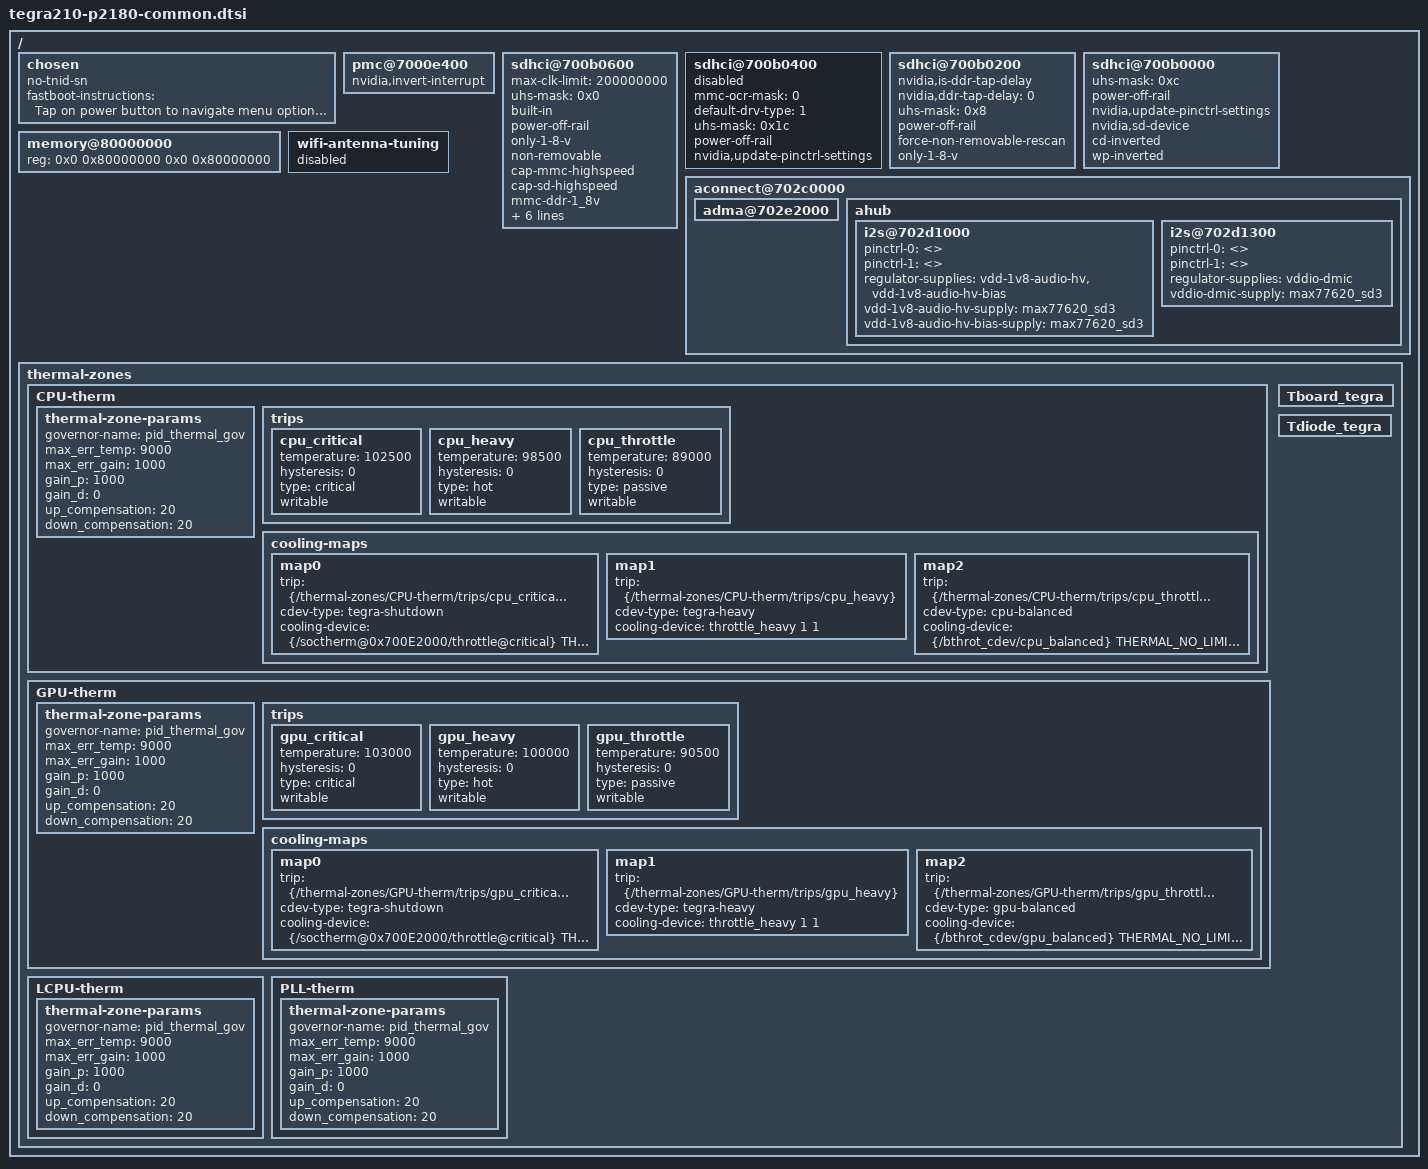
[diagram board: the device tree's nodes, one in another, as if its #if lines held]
/*
 * arch/arm64/boot/dts/tegra210-platforms/tegra210-p2180-common.dtsi
 *
 * Copyright (c) 2015-2016, NVIDIA CORPORATION.  All rights reserved.
 *
 * This program is free software; you can redistribute it and/or modify
 * it under the terms of the GNU General Public License as published by
 * the Free Software Foundation; version 2 of the License.
 *
 * This program is distributed in the hope that it will be useful, but WITHOUT
 * ANY WARRANTY; without even the implied warranty of MERCHANTABILITY or
 * FITNESS FOR A PARTICULAR PURPOSE.  See the GNU General Public License for
 * more details.
 *
 * You should have received a copy of the GNU General Public License along
 * with this program; if not, write to the Free Software Foundation, Inc.,
 * 51 Franklin Street, Fifth Floor, Boston, MA  02110-1301, USA.
 *
 */

#include <t210-common-platforms/tegra210-thermal-nct72-p2530.dtsi>
#include <tegra210-soc/tegra210-thermal-Tboard-Tdiode.dtsi>

/ {
	#address-cells = <2>;
	#size-cells = <2>;

	chosen {
		no-tnid-sn;
		fastboot-instructions = "Tap on power button to navigate menu options.\nHold down power button for 2 sec and release for selecting an option\n";
	};

	pmc@7000e400 {
		nvidia,invert-interrupt;
	};

	sdhci@700b0600 {
		max-clk-limit = <200000000>;
		uhs-mask = <0x0>;
		built-in;
		power-off-rail;
		only-1-8-v;
		non-removable;
		cap-mmc-highspeed;
		cap-sd-highspeed;
		mmc-ddr-1_8v;
		mmc-hs200-1_8v;
		mmc-hs400-1_8v;
		mmc-hs400-enhanced-strobe;
		no-sdio;
		no-sd;
		pll_source = "pll_p", "pll_c4_out2";
		status = "okay";
	};

	sdhci@700b0400 {
		mmc-ocr-mask = <0>;
		default-drv-type = <1>;
		uhs-mask = <0x1c>;
		power-off-rail;
		nvidia,update-pinctrl-settings;
		status = "disabled";
	};

	sdhci@700b0200 {
		nvidia,is-ddr-tap-delay;
		nvidia,ddr-tap-delay = <0>;
		uhs-mask = <0x8>;
		power-off-rail;
		force-non-removable-rescan;
		only-1-8-v;
		status = "okay";
	};

	sdhci@700b0000 {
		uhs-mask = <0xc>;
		power-off-rail;
		nvidia,update-pinctrl-settings;
		nvidia,sd-device;
		cd-inverted;
		wp-inverted;
		status = "okay";
	};

	memory@80000000 {
		device_type = "memory";
		reg = < 0x0 0x80000000 0x0 0x80000000 >;
	};

#if TEGRA_AUDIO_BUS_DT_VERSION >= DT_VERSION_2
	aconnect@702c0000 {
#endif
	adma@702e2000  {
		status = "okay";
	};


	ahub {
		i2s@702d1000 {
			pinctrl-names = "dap_active", "dap_inactive";
			pinctrl-0 = <>;
			pinctrl-1 = <>;
			regulator-supplies = "vdd-1v8-audio-hv", "vdd-1v8-audio-hv-bias";
			vdd-1v8-audio-hv-supply = <&max77620_sd3>;
			vdd-1v8-audio-hv-bias-supply = <&max77620_sd3>;
		};

		i2s@702d1300 {
			pinctrl-names = "dap_active", "dap_inactive";
			pinctrl-0 = <>;
			pinctrl-1 = <>;
			regulator-supplies = "vddio-dmic";
			vddio-dmic-supply = <&max77620_sd3>;
		};
	};
#if TEGRA_AUDIO_BUS_DT_VERSION >= DT_VERSION_2
	};
#endif

	wifi-antenna-tuning {
		status = "disabled";
	};

	thermal-zones {
		CPU-therm {
			thermal-zone-params {
				governor-name = "pid_thermal_gov";
				max_err_temp = <9000>;
				max_err_gain = <1000>;
				gain_p = <1000>;
				gain_d = <0>;
				up_compensation = <20>;
				down_compensation = <20>;
			};
			trips {
				cpu_critical {
					temperature = <102500>;
					hysteresis = <0>;
					type = "critical";
					writable;
				};
				cpu_heavy {
					temperature = <98500>;
					hysteresis = <0>;
					type = "hot";
					writable;
				};
				cpu_throttle {
					temperature = <89000>;
					hysteresis = <0>;
					type = "passive";
					writable;
				};
			};
			cooling-maps {
				map0 {
					trip = <&{/thermal-zones/CPU-therm/trips/cpu_critical}>;
					cdev-type = "tegra-shutdown";
					cooling-device = <&{/soctherm@0x700E2000/throttle@critical}
						THERMAL_NO_LIMIT THERMAL_NO_LIMIT>;
				};
				map1 {
					trip = <&{/thermal-zones/CPU-therm/trips/cpu_heavy}>;
					cdev-type = "tegra-heavy";
					cooling-device = <&throttle_heavy 1 1>;
				};
				map2 {
					trip = <&{/thermal-zones/CPU-therm/trips/cpu_throttle}>;
					cdev-type = "cpu-balanced";
					cooling-device = <&{/bthrot_cdev/cpu_balanced}
						THERMAL_NO_LIMIT THERMAL_NO_LIMIT>;
				};
			};
		};
		GPU-therm {
			thermal-zone-params {
				governor-name = "pid_thermal_gov";
				max_err_temp = <9000>;
				max_err_gain = <1000>;
				gain_p = <1000>;
				gain_d = <0>;
				up_compensation = <20>;
				down_compensation = <20>;
			};
			trips {
				gpu_critical {
					temperature = <103000>;
					hysteresis = <0>;
					type = "critical";
					writable;
				};
				gpu_heavy {
					temperature = <100000>;
					hysteresis = <0>;
					type = "hot";
					writable;
				};
				gpu_throttle {
					temperature = <90500>;
					hysteresis = <0>;
					type = "passive";
					writable;
				};
			};
			cooling-maps {
				map0 {
					trip = <&{/thermal-zones/GPU-therm/trips/gpu_critical}>;
					cdev-type = "tegra-shutdown";
					cooling-device = <&{/soctherm@0x700E2000/throttle@critical}
						THERMAL_NO_LIMIT THERMAL_NO_LIMIT>;
				};
				map1 {
					trip = <&{/thermal-zones/GPU-therm/trips/gpu_heavy}>;
					cdev-type = "tegra-heavy";
					cooling-device = <&throttle_heavy 1 1>;
				};
				map2 {
					trip = <&{/thermal-zones/GPU-therm/trips/gpu_throttle}>;
					cdev-type = "gpu-balanced";
					cooling-device = <&{/bthrot_cdev/gpu_balanced}
						THERMAL_NO_LIMIT THERMAL_NO_LIMIT>;
				};
			};
		};
		LCPU-therm {
			thermal-zone-params {
				governor-name = "pid_thermal_gov";
				max_err_temp = <9000>;
				max_err_gain = <1000>;
				gain_p = <1000>;
				gain_d = <0>;
				up_compensation = <20>;
				down_compensation = <20>;
			};
		};
		PLL-therm {
			thermal-zone-params {
				governor-name = "pid_thermal_gov";
				max_err_temp = <9000>;
				max_err_gain = <1000>;
				gain_p = <1000>;
				gain_d = <0>;
				up_compensation = <20>;
				down_compensation = <20>;
			};
		};

		Tboard_tegra {
			status = "okay";
		};
		Tdiode_tegra {
			status = "okay";
		};
	};

};

